# H5 register map
Vendor: Allwinner; Series: H5; File version: 0.1
CPU: 0, little endian, MPU, no FPU, 0 interrupt priority bits
Registers are 32-bit, read-write, reset 0x0 unless marked. A register's access mark holds for its fields unless they carry their own. Offsets are from the block's base; [hi:lo] are bit positions; lines under a group give offsets from that group; {n}, {i} and the like mark numbered series; 'fields as' and 'values as' point back to an identical list.

## TCON1
Base 0x01C0D000
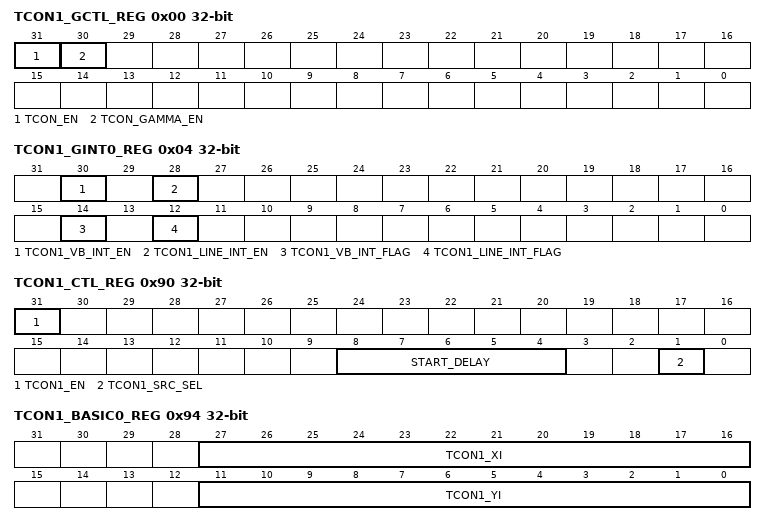
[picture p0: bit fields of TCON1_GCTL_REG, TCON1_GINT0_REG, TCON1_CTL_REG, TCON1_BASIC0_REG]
0x00 TCON1_GCTL_REG
  [31] TCON_EN — 0: Disable 1: Enable Whe it s disa led, the odule ill e eset to idle state.
    0=Disable; 1=Enable Whe it s disa led, the odule ill e eset to idle state
  [30] TCON_GAMMA_EN — 0: Disable 1: Enable
    0=Disable; 1=Enable
0x04 TCON1_GINT0_REG
  [30] TCON1_VB_INT_EN — 0: Disable 1: Enable
    0=Disable; 1=Enable
  [28] TCON1_LINE_INT_EN — 0: Disable 1: Enable
    0=Disable; 1=Enable
  [14] TCON1_VB_INT_FLAG — Asserted during vertical no-display period every frame. Write 0 to clear it.
  [12] TCON1_LINE_INT_FLAG — Trigger when SY1 match the current TCON1 scan line. Write 0 to clear it.
0x08 TCON1_GINT1_REG
  [11:0] TCON1_LINE_INT_NUM — Scan line for TCON1 line trigger(including inactive lines) Setting it for the specified line for trigger 1. Note: SY1 is writable only when LINE_TRG1 disable.
0x90 TCON1_CTL_REG — TCON1 Control Register
  [31] TCON1_EN — 0: Disable 1: Enable
    0=Disable; 1=Enable
  [8:4] START_DELAY — This is for DE1 and DE2
  [1] TCON1_SRC_SEL — 0: Reserved 1: BLUE data(FIFO2 disable,RGB = 0000FF)
    1=BLUE (BLUE data(FIFO2 disable,RGB = 0000FF))
0x94 TCON1_BASIC0_REG — TCON1 Basic Timing Register0
  [27:16] TCON1_XI — Source width is X+1
  [11:0] TCON1_YI — Source height is Y+1
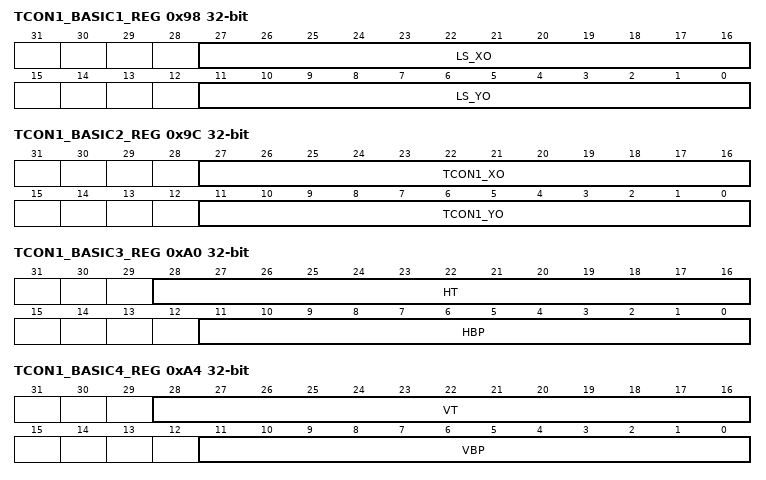
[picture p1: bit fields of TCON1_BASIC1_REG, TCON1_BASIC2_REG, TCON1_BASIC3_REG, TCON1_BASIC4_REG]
0x98 TCON1_BASIC1_REG — TCON1 Basic Timing Register1
  [27:16] LS_XO — Width is LS_XO+1
  [11:0] LS_YO — Width is LS_YO+1 Note: This version LS_YO = TCON1_YI
0x9C TCON1_BASIC2_REG — TCON1 Basic Timing Register2
  [27:16] TCON1_XO — Width is TCON1_XO+1
  [11:0] TCON1_YO — Height is TCON1_YO+1
0xA0 TCON1_BASIC3_REG — TCON1 Basic Timing Register3
  [28:16] HT — Horizontal total time Thcycle = (HT+1) * Thdclk
  [11:0] HBP — Horizontal back porch Thbp = (HBP +1) * Thdclk
0xA4 TCON1_BASIC4_REG — TCON1 Basic Timing Register4
  [28:16] VT — Horizontal total time (in HD line) Tvt = VT/2 * Th
  [11:0] VBP — Horizontal back porch (in HD line) Tvbp = (VBP +1) * Th
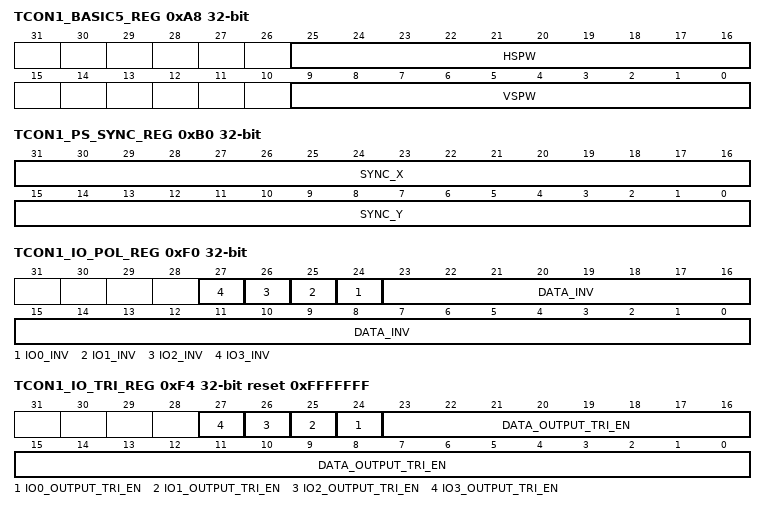
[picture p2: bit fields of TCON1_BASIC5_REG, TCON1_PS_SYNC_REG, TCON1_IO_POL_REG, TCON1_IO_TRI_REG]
0xA8 TCON1_BASIC5_REG — TCON1 Basic Timing Register5
  [25:16] HSPW — Horizontal Sync Pulse Width (in dclk) Thspw = (HSPW+1) * Tdclk Note: HT> (HSPW+1)
  [9:0] VSPW — Vertical Sync Pulse Width (in lines) Tvspw = (VSPW+1) * Th Note: VT/2 > (VSPW+1)
0xB0 TCON1_PS_SYNC_REG — TCON1 Sync Register
  [31:16] SYNC_X, [15:0] SYNC_Y
0xF0 TCON1_IO_POL_REG — TCON1 IO Polarity Register
  [n+24] IO{n}_INV (n=0..3) — 0: Not invert 1: Invert
    0=Not_invert; 1=Invert
  [23:0] DATA_INV — TCON output port D[23:0] polarity control,with independent bit control 0s: Normal polarity 1s: Invert the specify output
0xF4 TCON1_IO_TRI_REG reset 0xFFFFFFF — TCON1 IO Trigger Register
  [n+24] IO{n}_OUTPUT_TRI_EN (n=0..3) — 0: Enable 1: Disable
    0=Enable; 1=Disable
  [23:0] DATA_OUTPUT_TRI_EN — TCON output port D[23:0] output enable,with independent bit control. 0s: Enable 1s: Disable
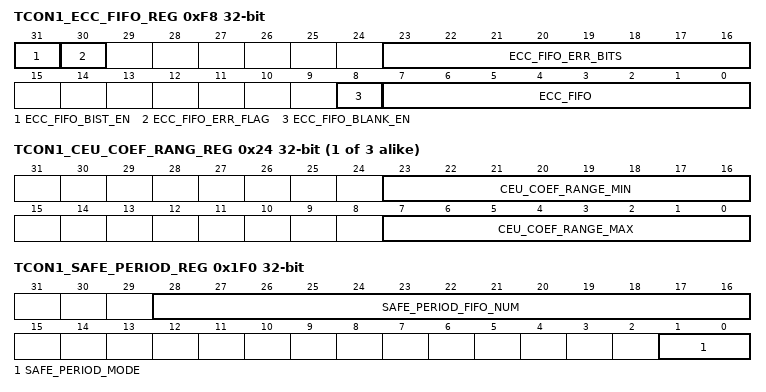
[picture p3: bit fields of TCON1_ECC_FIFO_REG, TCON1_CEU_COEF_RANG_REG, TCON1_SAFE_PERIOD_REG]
0xF8 TCON1_ECC_FIFO_REG reset not defined
  [31] ECC_FIFO_BIST_EN — 0: Disable 1: Enable
    0=Disable; 1=Enable
  [30] ECC_FIFO_ERR_FLAG
  [23:16] ECC_FIFO_ERR_BITS
  [8] ECC_FIFO_BLANK_EN — 0: Disable ECC function in blanking 1: Enable ECC function in blanking ECC fu tio is te t to t igge i la ki g a ea at h ode, set he i h mode.
    0=Disable ECC function in blanking; 1=Enable ECC function in blanking ECC fu tio is te t to t igge i la ki g a ea at h ode, set he i h mode
  [7:0] ECC_FIFO — Bit3 0: Enable 1: Disable
0x100 TCON1_CEU_CTL_REG
  [31] CEU_EN — 0: Bypass 1: Enable
    0=Bypass; 1=Enable
0x110 TCON1_CEU_COEF_MUL_REG_0
  [12:0] CEU_COEF_MUL_VALUE — Signed 13bit value, range of (-16,16) N=0: Rr N=1: Rg N=2: Rb N=4: Gr N=5: Gg N=6: Gb N=8: Br N=9: Bg N=10: Bb
0x114 TCON1_CEU_COEF_MUL_REG_1 — TCON1_CEU_COEF_MUL_REG_0
  fields as TCON1_CEU_COEF_MUL_REG_0
0x118 TCON1_CEU_COEF_MUL_REG_2 — TCON1_CEU_COEF_MUL_REG_0
  fields as TCON1_CEU_COEF_MUL_REG_0
{0x11C+0x10*i} _N[{i}] (i=0..2) group
  0x00 TCON1_CEU_COEF_ADD_REG
    [18:0] CEU_COEF_ADD_VALUE — Signed 19bit value, range of (-16384, 16384) N=0: Rc N=1: Gc N=2: Bc
  0x24 TCON1_CEU_COEF_RANG_REG
    [23:16] CEU_COEF_RANGE_MIN — Unsigned 8bit value, range of [0,255]
    [7:0] CEU_COEF_RANGE_MAX — Unsigned 8bit value, range of [0,255]
  0x1E8 TCON1_FILL_BEGIN_REG — TCON1 Fill Data Begin Register(N=0,1,2)
    [23:0] FILL_BEGIN
  0x1EC TCON1_FILL_END_REG — TCON1 Fill Data End Register(N=0,1,2)
    [23:0] FILL_END
  0x1F0 TCON1_FILL_DATA_REG
    [23:0] FILL_VALUE
{0x110+4i} TCON1_CEU_COEF_MUL_REG_{i} (i=4..6) — TCON1_CEU_COEF_MUL_REG_0
  fields as TCON1_CEU_COEF_MUL_REG_0
{0x110+4i} TCON1_CEU_COEF_MUL_REG_{i} (i=8..10) — TCON1_CEU_COEF_MUL_REG_0
  fields as TCON1_CEU_COEF_MUL_REG_0
0x1F0 TCON1_SAFE_PERIOD_REG
  [28:16] SAFE_PERIOD_FIFO_NUM
  [1:0] SAFE_PERIOD_MODE — 00: Unsafe 01: Safe 10: Safe at ECC_FIFO_CUR_NUM > SAFE_PERIOD_FIFO_NUM 11: Safe at 2 and safe at sync active
0x300 TCON1_FILL_CTL_REG — TCON1 Fill Data Control Register
  [31] TCON1_FILL_EN — 0: Bypass 1: Enable
    0=Bypass; 1=Enable
